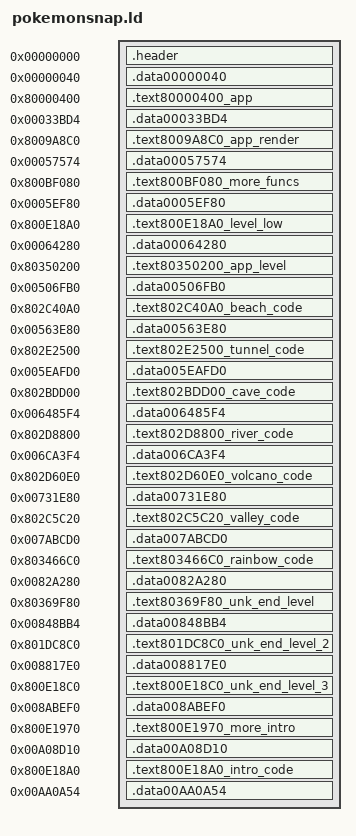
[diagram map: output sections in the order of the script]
/* Pokemon Snap (U) [!] linker script
 * generated by n64split v0.4a - N64 ROM splitter */

SECTIONS
{
   /* header and boot */
   .header 0x0 : AT(0x0) {
      * (.header);
      * (.boot);
   }

   /* 0x00000000 000040-001000 [FC0] */
   .data00000040 0x00000040 : AT(0x000040) {
      build/bin/pokemonsnap.000040.boot.o(.data);
   }

   /* 0x80000400 001000-033BD4 [32BD4] */
   .text80000400_app 0x80000400 : AT(0x001000) {
      build/asm/app.o(.text80000400_app);
   }

   /* 0x00000000 033BD4-046270 [1269C] */
   .data00033BD4 0x00033BD4 : AT(0x033BD4) {
      build/bin/pokemonsnap.033BD4.o(.data);
   }

   /* 0x8009A8C0 046270-057574 [11304] */
   .text8009A8C0_app_render 0x8009A8C0 : AT(0x046270) {
      build/asm/app_render.o(.text8009A8C0_app_render);
   }

   /* 0x00000000 057574-05BF20 [49AC] */
   .data00057574 0x00057574 : AT(0x057574) {
      build/bin/pokemonsnap.057574.o(.data);
   }

   /* 0x800BF080 05BF20-05EF80 [3060] */
   .text800BF080_more_funcs 0x800BF080 : AT(0x05BF20) {
      build/asm/more_funcs.o(.text800BF080_more_funcs);
   }

   /* 0x00000000 05EF80-05F050 [D0] */
   .data0005EF80 0x0005EF80 : AT(0x05EF80) {
      build/bin/pokemonsnap.05EF80.o(.data);
   }

   /* 0x800E18A0 05F050-064280 [5230] */
   .text800E18A0_level_low 0x800E18A0 : AT(0x05F050) {
      build/asm/level_low.o(.text800E18A0_level_low);
   }

   /* 0x00000000 064280-4F0610 [48C390] */
   .data00064280 0x00064280 : AT(0x064280) {
      build/bin/pokemonsnap.064280.o(.data);
   }

   /* 0x80350200 4F0610-506FB0 [169A0] */
   .text80350200_app_level 0x80350200 : AT(0x4F0610) {
      build/asm/app_level.o(.text80350200_app_level);
   }

   /* 0x00000000 506FB0-55C110 [55160] */
   .data00506FB0 0x00506FB0 : AT(0x506FB0) {
      build/bin/pokemonsnap.506FB0.o(.data);
   }

   /* 0x802C40A0 55C110-563E80 [7D70] */
   .text802C40A0_beach_code 0x802C40A0 : AT(0x55C110) {
      build/asm/beach_code.o(.text802C40A0_beach_code);
   }

   /* 0x00000000 563E80-5DF5D0 [7B750] */
   .data00563E80 0x00563E80 : AT(0x563E80) {
      build/bin/pokemonsnap.563E80.o(.data);
   }

   /* 0x802E2500 5DF5D0-5EAFD0 [BA00] */
   .text802E2500_tunnel_code 0x802E2500 : AT(0x5DF5D0) {
      build/asm/tunnel_code.o(.text802E2500_tunnel_code);
   }

   /* 0x00000000 5EAFD0-6401B0 [551E0] */
   .data005EAFD0 0x005EAFD0 : AT(0x5EAFD0) {
      build/bin/pokemonsnap.5EAFD0.o(.data);
   }

   /* 0x802BDD00 6401B0-6485F4 [8444] */
   .text802BDD00_cave_code 0x802BDD00 : AT(0x6401B0) {
      build/asm/cave_code.o(.text802BDD00_cave_code);
   }

   /* 0x00000000 6485F4-6C05E0 [77FEC] */
   .data006485F4 0x006485F4 : AT(0x6485F4) {
      build/bin/pokemonsnap.6485F4.o(.data);
   }

   /* 0x802D8800 6C05E0-6CA3F4 [9E14] */
   .text802D8800_river_code 0x802D8800 : AT(0x6C05E0) {
      build/asm/river_code.o(.text802D8800_river_code);
   }

   /* 0x00000000 6CA3F4-7272E0 [5CEEC] */
   .data006CA3F4 0x006CA3F4 : AT(0x6CA3F4) {
      build/bin/pokemonsnap.6CA3F4.o(.data);
   }

   /* 0x802D60E0 7272E0-731E80 [ABA0] */
   .text802D60E0_volcano_code 0x802D60E0 : AT(0x7272E0) {
      build/asm/volcano_code.o(.text802D60E0_volcano_code);
   }

   /* 0x00000000 731E80-79F1B0 [6D330] */
   .data00731E80 0x00731E80 : AT(0x731E80) {
      build/bin/pokemonsnap.731E80.o(.data);
   }

   /* 0x802C5C20 79F1B0-7ABCD0 [CB20] */
   .text802C5C20_valley_code 0x802C5C20 : AT(0x79F1B0) {
      build/asm/valley_code.o(.text802C5C20_valley_code);
   }

   /* 0x00000000 7ABCD0-825E30 [7A160] */
   .data007ABCD0 0x007ABCD0 : AT(0x7ABCD0) {
      build/bin/pokemonsnap.7ABCD0.o(.data);
   }

   /* 0x803466C0 825E30-82A280 [4450] */
   .text803466C0_rainbow_code 0x803466C0 : AT(0x825E30) {
      build/asm/rainbow_code.o(.text803466C0_rainbow_code);
   }

   /* 0x00000000 82A280-83D730 [134B0] */
   .data0082A280 0x0082A280 : AT(0x82A280) {
      build/bin/pokemonsnap.82A280.o(.data);
   }

   /* 0x80369F80 83D730-848BB4 [B484] */
   .text80369F80_unk_end_level 0x80369F80 : AT(0x83D730) {
      build/asm/unk_end_level.o(.text80369F80_unk_end_level);
   }

   /* 0x00000000 848BB4-87A0B0 [314FC] */
   .data00848BB4 0x00848BB4 : AT(0x848BB4) {
      build/bin/pokemonsnap.848BB4.o(.data);
   }

   /* 0x801DC8C0 87A0B0-8817E0 [7730] */
   .text801DC8C0_unk_end_level_2 0x801DC8C0 : AT(0x87A0B0) {
      build/asm/unk_end_level_2.o(.text801DC8C0_unk_end_level_2);
   }

   /* 0x00000000 8817E0-8A70E0 [25900] */
   .data008817E0 0x008817E0 : AT(0x8817E0) {
      build/bin/pokemonsnap.8817E0.o(.data);
   }

   /* 0x800E18C0 8A70E0-8ABEF0 [4E10] */
   .text800E18C0_unk_end_level_3 0x800E18C0 : AT(0x8A70E0) {
      build/asm/unk_end_level_3.o(.text800E18C0_unk_end_level_3);
   }

   /* 0x00000000 8ABEF0-A084B0 [15C5C0] */
   .data008ABEF0 0x008ABEF0 : AT(0x8ABEF0) {
      build/bin/pokemonsnap.8ABEF0.o(.data);
   }

   /* 0x800E1970 A084B0-A08D10 [860] */
   .text800E1970_more_intro 0x800E1970 : AT(0xA084B0) {
      build/asm/more_intro.o(.text800E1970_more_intro);
   }

   /* 0x00000000 A08D10-AA0650 [97940] */
   .data00A08D10 0x00A08D10 : AT(0xA08D10) {
      build/bin/pokemonsnap.A08D10.o(.data);
   }

   /* 0x800E18A0 AA0650-AA0A54 [404] */
   .text800E18A0_intro_code 0x800E18A0 : AT(0xAA0650) {
      build/asm/intro_code.o(.text800E18A0_intro_code);
   }

   /* 0x00000000 AA0A54-1000000 [55F5AC] */
   .data00AA0A54 0x00AA0A54 : AT(0xAA0A54) {
      build/bin/pokemonsnap.AA0A54.o(.data);
   }

   /* Discard everything not specifically mentioned above. */
   /DISCARD/ :
   {
      *(*);
   }
}
